# myChip register map
Vendor: ARM Ltd.; Series: ARMCM3; File version: 1.2
CPU: CM3 r2p1, little endian, no MPU, no FPU, 3 interrupt priority bits
Registers are 32-bit, read-write, reset 0x0 unless marked. A register's access mark holds for its fields unless they carry their own. Offsets are from the block's base; [hi:lo] are bit positions; {n}, {i} and the like mark numbered series.

## HRPWM_COM
Base 0x4003BF00
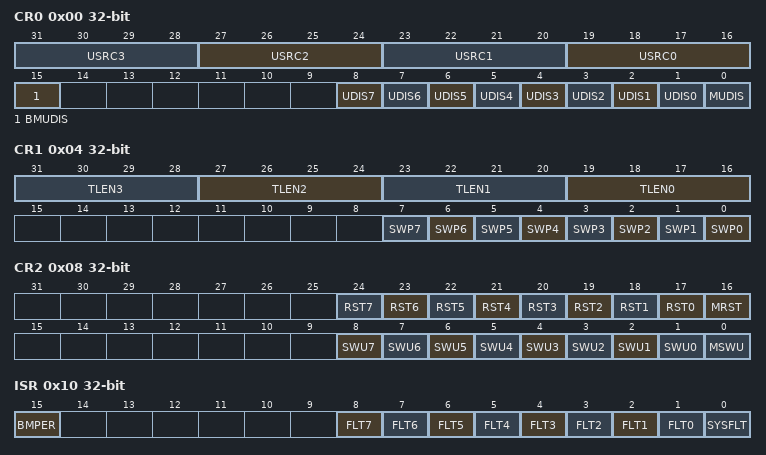
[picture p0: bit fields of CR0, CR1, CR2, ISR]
0x00 CR0 — HRPWM Control Register0
  [4n+19:4n+16] USRC{n} (n=0..3) — Adc Trigger {n} 更新来源
  [15] BMUDIS — Burst Mode 更新禁止
  [n+1] UDIS{n} (n=0..7) — PWM{n} 更新禁止
  [0] MUDIS — Master PWM 更新禁止
0x04 CR1 — HRPWM Control Register1
  [4n+19:4n+16] TLEN{n} (n=0..3) — Adc Trigger {n} 事件长度
  [n] SWP{n} (n=0..7) — PWM{n} 输出交换
0x08 CR2 — HRPWM Control Register2
  [n+17] RST{n} (n=0..7) — PWM{n} 软件复位
  [16] MRST — Master PWM 软件复位
  [n+1] SWU{n} (n=0..7) — PWM{n} 软件更新
  [0] MSWU — Master PWM 软件更新
0x10 ISR — HRPWM Interrupt Status Register
  [15] BMPER — Burst Mode Period 中断标志
  [n+1] FLT{n} (n=0..7) — Fault {n} 中断标志
  [0] SYSFLT — System Fault 中断标志
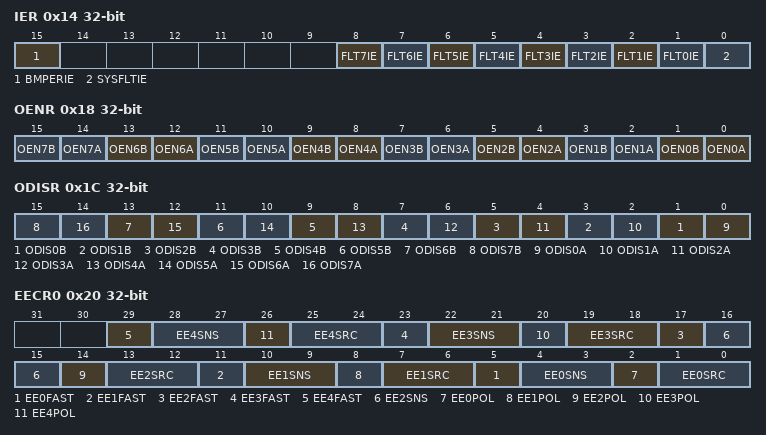
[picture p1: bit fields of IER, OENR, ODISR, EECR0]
0x14 IER — HRPWM Interrupt Enable Register
  [15] BMPERIE — Burst Mode Period 中断使能
  [n+1] FLT{n}IE (n=0..7) — Fault {n} 中断使能
  [0] SYSFLTIE — System Fault 中断使能
0x18 OENR — HRPWM Output Enable Register
  [2n+1] OEN{n}B (n=0..7) — PWM{n} Out B启动
  [2n] OEN{n}A (n=0..7) — PWM{n} Out A启动
0x1C ODISR — HRPWM Output Disable Register
  [2n+1] ODIS{n}B (n=0..7) — PWM{n} Out B停止
  [2n] ODIS{n}A (n=0..7) — PWM{n} Out A停止
0x20 EECR0 — HRPWM External Event Control Register0
  [6n+5] EE{n}FAST (n=0..4) — Event {n} 快速模式
  [6n+4:6n+3] EE{n}SNS (n=0..4) — Event {n} 输入有效沿
  [6n+2] EE{n}POL (n=0..4) — Event {n} 输入极性
  [6n+1:6n] EE{n}SRC (n=0..4) — Event {n} 输入来源
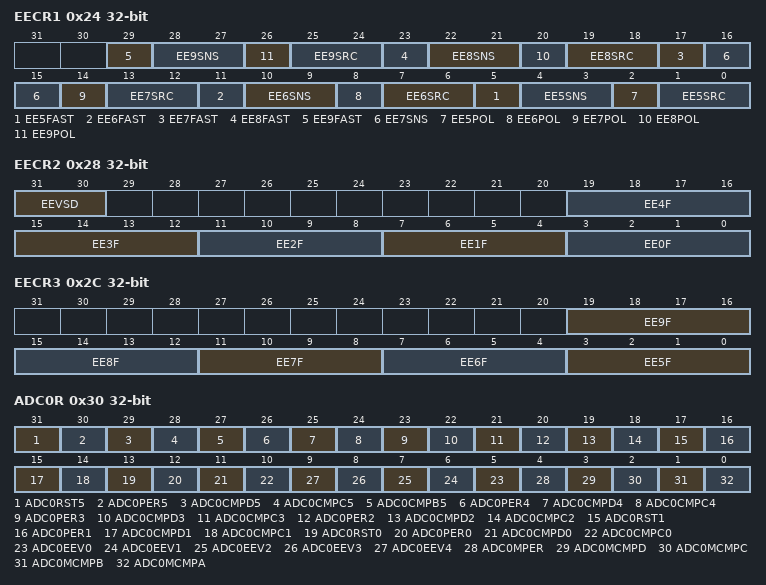
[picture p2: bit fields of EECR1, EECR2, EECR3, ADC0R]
0x24 EECR1 — HRPWM External Event Control Register1
  [6n-25] EE{n}FAST (n=5..9) — Event {n} 快速模式
  [6n-26:6n-27] EE{n}SNS (n=5..9) — Event {n} 输入有效沿
  [6n-28] EE{n}POL (n=5..9) — Event {n} 输入极性
  [6n-29:6n-30] EE{n}SRC (n=5..9) — Event {n} 输入来源
0x28 EECR2 — HRPWM External Event Control Register2
  [31:30] EEVSD — Event 采样时钟分频比例
  [4n+3:4n] EE{n}F (n=0..4) — Event {n} 滤波长度
0x2C EECR3 — HRPWM External Event Control Register3
  [4n-17:4n-20] EE{n}F (n=5..9) — Event {n} 滤波长度
0x30 ADC0R — HRPWM ADC Trigger Register 0
  [31] ADC0RST5 — PWM5 Reset/RollOver事件会产生Adc Trigger 0
  [30] ADC0PER5 — PWM5 Period事件会产生Adc Trigger 0
  [29] ADC0CMPD5 — PWM5 Compare D事件会产生Adc Trigger 0
  [28] ADC0CMPC5 — PWM5 Compare C事件会产生Adc Trigger 0
  [27] ADC0CMPB5 — PWM5 Compare B事件会产生Adc Trigger 0
  [26] ADC0PER4 — PWM4 Period事件会产生Adc Trigger 0
  [25] ADC0CMPD4 — PWM4 Compare D事件会产生Adc Trigger 0
  [24] ADC0CMPC4 — PWM4 Compare C事件会产生Adc Trigger 0
  [23] ADC0PER3 — PWM3 Period事件会产生Adc Trigger 0
  [22] ADC0CMPD3 — PWM3 Compare D事件会产生Adc Trigger 0
  [21] ADC0CMPC3 — PWM3 Compare C事件会产生Adc Trigger 0
  [20] ADC0PER2 — PWM2 Period事件会产生Adc Trigger 0
  [19] ADC0CMPD2 — PWM2 Compare D事件会产生Adc Trigger 0
  [18] ADC0CMPC2 — PWM2 Compare C事件会产生Adc Trigger 0
  [17] ADC0RST1 — PWM1 Reset/RollOver事件会产生Adc Trigger 0
  [16] ADC0PER1 — PWM1 Period事件会产生Adc Trigger 0
  [15] ADC0CMPD1 — PWM1 Compare D事件会产生Adc Trigger 0
  [14] ADC0CMPC1 — PWM1 Compare C事件会产生Adc Trigger 0
  [13] ADC0RST0 — PWM0 Reset/RollOver事件会产生Adc Trigger 0
  [12] ADC0PER0 — PWM0 Period事件会产生Adc Trigger 0
  [11] ADC0CMPD0 — PWM0 Compare D事件会产生Adc Trigger 0
  [10] ADC0CMPC0 — PWM0 Compare C事件会产生Adc Trigger 0
  [n+5] ADC0EEV{n} (n=0..4) — External Event {n}事件会产生Adc Trigger 0
  [4] ADC0MPER — Master PWM Period事件会产生Adc Trigger 0
  [3] ADC0MCMPD — Master PWM Compare D事件会产生Adc Trigger 0
  [2] ADC0MCMPC — Master PWM Compare C事件会产生Adc Trigger 0
  [1] ADC0MCMPB — Master PWM Compare B事件会产生Adc Trigger 0
  [0] ADC0MCMPA — Master PWM Compare A事件会产生Adc Trigger 0
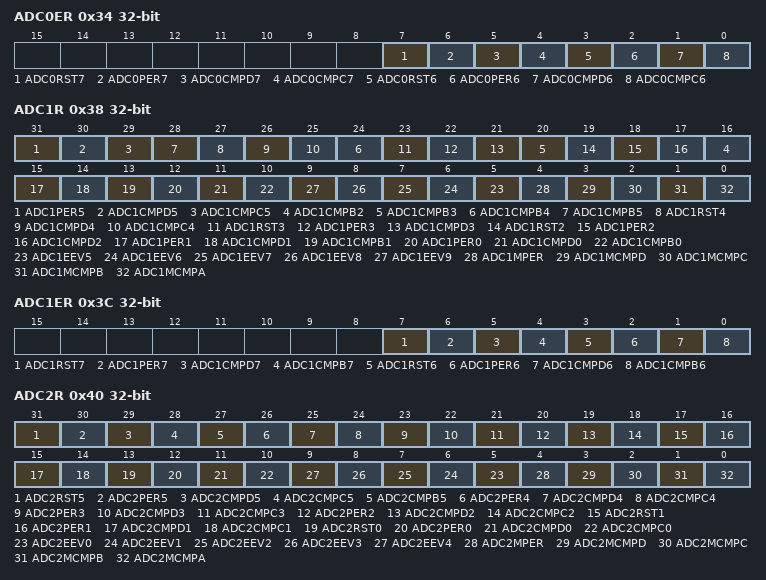
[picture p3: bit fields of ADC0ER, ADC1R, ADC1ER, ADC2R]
0x34 ADC0ER — HRPWM ADC Trigger Extended Register 0
  [7] ADC0RST7 — PWM7 Reset/RollOver事件会产生Adc Trigger 0
  [6] ADC0PER7 — PWM7 Period事件会产生Adc Trigger 0
  [5] ADC0CMPD7 — PWM7 Compare D事件会产生Adc Trigger 0
  [4] ADC0CMPC7 — PWM7 Compare C事件会产生Adc Trigger 0
  [3] ADC0RST6 — PWM6 Reset/RollOver事件会产生Adc Trigger 0
  [2] ADC0PER6 — PWM6 Period事件会产生Adc Trigger 0
  [1] ADC0CMPD6 — PWM6 Compare D事件会产生Adc Trigger 0
  [0] ADC0CMPC6 — PWM6 Compare C事件会产生Adc Trigger 0
0x38 ADC1R — HRPWM ADC Trigger Register 1
  [31] ADC1PER5 — PWM5 Period事件会产生Adc Trigger 1
  [30] ADC1CMPD5 — PWM5 Compare D事件会产生Adc Trigger 1
  [29] ADC1CMPC5 — PWM5 Compare C事件会产生Adc Trigger 1
  [4n+8] ADC1CMPB{n} (n=2..5) — PWM{n} Compare B事件会产生Adc Trigger 1
  [27] ADC1RST4 — PWM4 Reset/RollOver事件会产生Adc Trigger 1
  [26] ADC1CMPD4 — PWM4 Compare D事件会产生Adc Trigger 1
  [25] ADC1CMPC4 — PWM4 Compare C事件会产生Adc Trigger 1
  [23] ADC1RST3 — PWM3 Reset/RollOver事件会产生Adc Trigger 1
  [22] ADC1PER3 — PWM3 Period事件会产生Adc Trigger 1
  [21] ADC1CMPD3 — PWM3 Compare D事件会产生Adc Trigger 1
  [19] ADC1RST2 — PWM2 Reset/RollOver事件会产生Adc Trigger 1
  [18] ADC1PER2 — PWM2 Period事件会产生Adc Trigger 1
  [17] ADC1CMPD2 — PWM2 Compare D事件会产生Adc Trigger 1
  [15] ADC1PER1 — PWM1 Period事件会产生Adc Trigger 1
  [14] ADC1CMPD1 — PWM1 Compare D事件会产生Adc Trigger 1
  [13] ADC1CMPB1 — PWM1 Compare B事件会产生Adc Trigger 1
  [12] ADC1PER0 — PWM0 Period事件会产生Adc Trigger 1
  [11] ADC1CMPD0 — PWM0 Compare D事件会产生Adc Trigger 1
  [10] ADC1CMPB0 — PWM0 Compare B事件会产生Adc Trigger 1
  [n] ADC1EEV{n} (n=5..9) — External Event {n}事件会产生Adc Trigger 1
  [4] ADC1MPER — Master PWM Period事件会产生Adc Trigger 1
  [3] ADC1MCMPD — Master PWM Compare D事件会产生Adc Trigger 1
  [2] ADC1MCMPC — Master PWM Compare C事件会产生Adc Trigger 1
  [1] ADC1MCMPB — Master PWM Compare B事件会产生Adc Trigger 1
  [0] ADC1MCMPA — Master PWM Compare A事件会产生Adc Trigger 1
0x3C ADC1ER — HRPWM ADC Trigger Extended Register 1
  [7] ADC1RST7 — PWM7 Reset/RollOver事件会产生Adc Trigger 1
  [6] ADC1PER7 — PWM7 Period事件会产生Adc Trigger 1
  [5] ADC1CMPD7 — PWM7 Compare D事件会产生Adc Trigger 1
  [4] ADC1CMPB7 — PWM7 Compare B事件会产生Adc Trigger 1
  [3] ADC1RST6 — PWM6 Reset/RollOver事件会产生Adc Trigger 1
  [2] ADC1PER6 — PWM6 Period事件会产生Adc Trigger 1
  [1] ADC1CMPD6 — PWM6 Compare D事件会产生Adc Trigger 1
  [0] ADC1CMPB6 — PWM6 Compare B事件会产生Adc Trigger 1
0x40 ADC2R — HRPWM ADC Trigger Register 2
  [31] ADC2RST5 — PWM5 Reset/RollOver事件会产生Adc Trigger 2
  [30] ADC2PER5 — PWM5 Period事件会产生Adc Trigger 2
  [29] ADC2CMPD5 — PWM5 Compare D事件会产生Adc Trigger 2
  [28] ADC2CMPC5 — PWM5 Compare C事件会产生Adc Trigger 2
  [27] ADC2CMPB5 — PWM5 Compare B事件会产生Adc Trigger 2
  [26] ADC2PER4 — PWM4 Period事件会产生Adc Trigger 2
  [25] ADC2CMPD4 — PWM4 Compare D事件会产生Adc Trigger 2
  [24] ADC2CMPC4 — PWM4 Compare C事件会产生Adc Trigger 2
  [23] ADC2PER3 — PWM3 Period事件会产生Adc Trigger 2
  [22] ADC2CMPD3 — PWM3 Compare D事件会产生Adc Trigger 2
  [21] ADC2CMPC3 — PWM3 Compare C事件会产生Adc Trigger 2
  [20] ADC2PER2 — PWM2 Period事件会产生Adc Trigger 2
  [19] ADC2CMPD2 — PWM2 Compare D事件会产生Adc Trigger 2
  [18] ADC2CMPC2 — PWM2 Compare C事件会产生Adc Trigger 2
  [17] ADC2RST1 — PWM1 Reset/RollOver事件会产生Adc Trigger 2
  [16] ADC2PER1 — PWM1 Period事件会产生Adc Trigger 2
  [15] ADC2CMPD1 — PWM1 Compare D事件会产生Adc Trigger 2
  [14] ADC2CMPC1 — PWM1 Compare C事件会产生Adc Trigger 2
  [13] ADC2RST0 — PWM0 Reset/RollOver事件会产生Adc Trigger 2
  [12] ADC2PER0 — PWM0 Period事件会产生Adc Trigger 2
  [11] ADC2CMPD0 — PWM0 Compare D事件会产生Adc Trigger 2
  [10] ADC2CMPC0 — PWM0 Compare C事件会产生Adc Trigger 2
  [n+5] ADC2EEV{n} (n=0..4) — External Event {n}事件会产生Adc Trigger 2
  [4] ADC2MPER — Master PWM Period事件会产生Adc Trigger 2
  [3] ADC2MCMPD — Master PWM Compare D事件会产生Adc Trigger 2
  [2] ADC2MCMPC — Master PWM Compare C事件会产生Adc Trigger 2
  [1] ADC2MCMPB — Master PWM Compare B事件会产生Adc Trigger 2
  [0] ADC2MCMPA — Master PWM Compare A事件会产生Adc Trigger 2
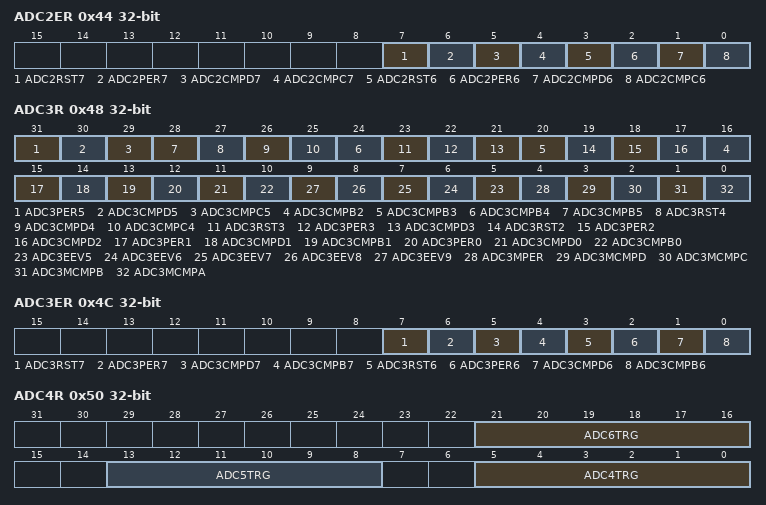
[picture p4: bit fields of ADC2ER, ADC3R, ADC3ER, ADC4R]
0x44 ADC2ER — HRPWM ADC Trigger Extended Register 2
  [7] ADC2RST7 — PWM7 Reset/RollOver事件会产生Adc Trigger 2
  [6] ADC2PER7 — PWM7 Period事件会产生Adc Trigger 2
  [5] ADC2CMPD7 — PWM7 Compare D事件会产生Adc Trigger 2
  [4] ADC2CMPC7 — PWM7 Compare C事件会产生Adc Trigger 2
  [3] ADC2RST6 — PWM6 Reset/RollOver事件会产生Adc Trigger 2
  [2] ADC2PER6 — PWM6 Period事件会产生Adc Trigger 2
  [1] ADC2CMPD6 — PWM6 Compare D事件会产生Adc Trigger 2
  [0] ADC2CMPC6 — PWM6 Compare C事件会产生Adc Trigger 2
0x48 ADC3R — HRPWM ADC Trigger Register 3
  [31] ADC3PER5 — PWM5 Period事件会产生Adc Trigger 3
  [30] ADC3CMPD5 — PWM5 Compare D事件会产生Adc Trigger 3
  [29] ADC3CMPC5 — PWM5 Compare C事件会产生Adc Trigger 3
  [4n+8] ADC3CMPB{n} (n=2..5) — PWM{n} Compare B事件会产生Adc Trigger 3
  [27] ADC3RST4 — PWM4 Reset/RollOver事件会产生Adc Trigger 3
  [26] ADC3CMPD4 — PWM4 Compare D事件会产生Adc Trigger 3
  [25] ADC3CMPC4 — PWM4 Compare C事件会产生Adc Trigger 3
  [23] ADC3RST3 — PWM3 Reset/RollOver事件会产生Adc Trigger 3
  [22] ADC3PER3 — PWM3 Period事件会产生Adc Trigger 3
  [21] ADC3CMPD3 — PWM3 Compare D事件会产生Adc Trigger 3
  [19] ADC3RST2 — PWM2 Reset/RollOver事件会产生Adc Trigger 3
  [18] ADC3PER2 — PWM2 Period事件会产生Adc Trigger 3
  [17] ADC3CMPD2 — PWM2 Compare D事件会产生Adc Trigger 3
  [15] ADC3PER1 — PWM1 Period事件会产生Adc Trigger 3
  [14] ADC3CMPD1 — PWM1 Compare D事件会产生Adc Trigger 3
  [13] ADC3CMPB1 — PWM1 Compare B事件会产生Adc Trigger 3
  [12] ADC3PER0 — PWM0 Period事件会产生Adc Trigger 3
  [11] ADC3CMPD0 — PWM0 Compare D事件会产生Adc Trigger 3
  [10] ADC3CMPB0 — PWM0 Compare B事件会产生Adc Trigger 3
  [n] ADC3EEV{n} (n=5..9) — External Event {n}事件会产生Adc Trigger 3
  [4] ADC3MPER — Master PWM Period事件会产生Adc Trigger 3
  [3] ADC3MCMPD — Master PWM Compare D事件会产生Adc Trigger 3
  [2] ADC3MCMPC — Master PWM Compare C事件会产生Adc Trigger 3
  [1] ADC3MCMPB — Master PWM Compare B事件会产生Adc Trigger 3
  [0] ADC3MCMPA — Master PWM Compare A事件会产生Adc Trigger 3
0x4C ADC3ER — HRPWM ADC Trigger Extended Register 3
  [7] ADC3RST7 — PWM7 Reset/RollOver事件会产生Adc Trigger 3
  [6] ADC3PER7 — PWM7 Period事件会产生Adc Trigger 3
  [5] ADC3CMPD7 — PWM7 Compare D事件会产生Adc Trigger 3
  [4] ADC3CMPB7 — PWM7 Compare B事件会产生Adc Trigger 3
  [3] ADC3RST6 — PWM6 Reset/RollOver事件会产生Adc Trigger 3
  [2] ADC3PER6 — PWM6 Period事件会产生Adc Trigger 3
  [1] ADC3CMPD6 — PWM6 Compare D事件会产生Adc Trigger 3
  [0] ADC3CMPB6 — PWM6 Compare B事件会产生Adc Trigger 3
0x50 ADC4R — HRPWM ADC Trigger Register 4
  [21:16] ADC6TRG — Adc Trigger 6 来源
  [13:8] ADC5TRG — Adc Trigger 5 来源
  [5:0] ADC4TRG — Adc Trigger 4 来源
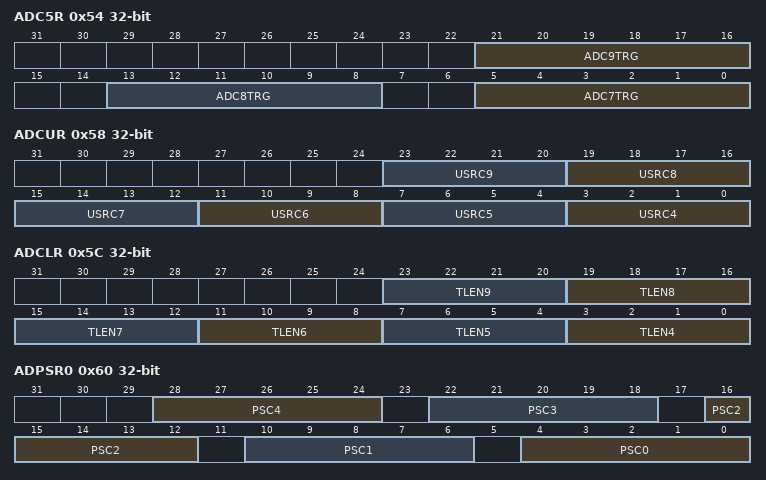
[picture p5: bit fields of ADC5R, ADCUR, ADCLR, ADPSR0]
0x54 ADC5R — HRPWM ADC Trigger Register 5
  [21:16] ADC9TRG — Adc Trigger 9 来源
  [13:8] ADC8TRG — Adc Trigger 8 来源
  [5:0] ADC7TRG — Adc Trigger 7 来源
0x58 ADCUR — HRPWM ADC Update Register
  [4n-13:4n-16] USRC{n} (n=4..9) — Adc Trigger {n} 更新来源
0x5C ADCLR — HRPWM ADC Length Register
  [4n-13:4n-16] TLEN{n} (n=4..9) — Adc Trigger {n} 事件长度
0x60 ADPSR0 — HRPWM ADC Trigger Post Scaler Register0
  [6n+4:6n] PSC{n} (n=0..4) — Adc Trigger {n} 降采样比例
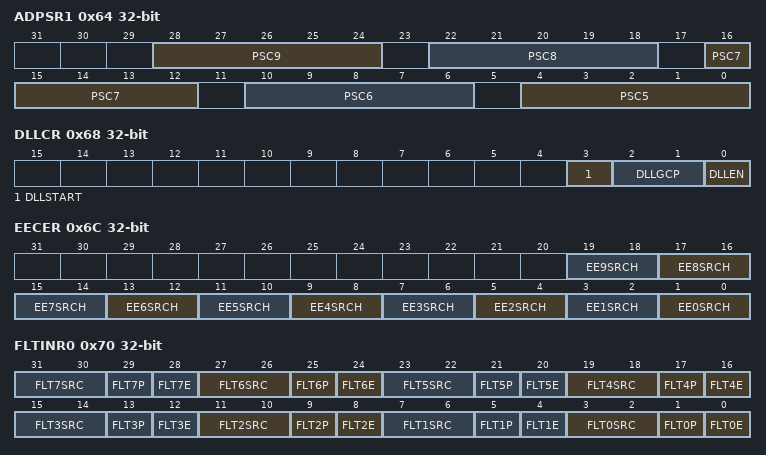
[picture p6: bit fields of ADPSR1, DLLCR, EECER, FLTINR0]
0x64 ADPSR1 — HRPWM ADC Trigger Post Scaler Register1
  [6n-26:6n-30] PSC{n} (n=5..9) — Adc Trigger {n} 降采样比例
0x68 DLLCR — HRPWM DLL Control Register
  [3] DLLSTART — DLL 启动位
  [2:1] DLLGCP — DLL 电流选择位
  [0] DLLEN — DLL 使能位
0x6C EECER — HRPWM External Event Control Extended Register
  [2n+1:2n] EE{n}SRCH (n=0..9) — Event {n} 输入来源高位
0x70 FLTINR0 — HRPWM Fault Input Register0
  [4n+3:4n+2] FLT{n}SRC (n=0..7) — Fault {n} 输入来源
  [4n+1] FLT{n}P (n=0..7) — Fault {n} 输入极性
  [4n] FLT{n}E (n=0..7) — Fault {n} 输入使能
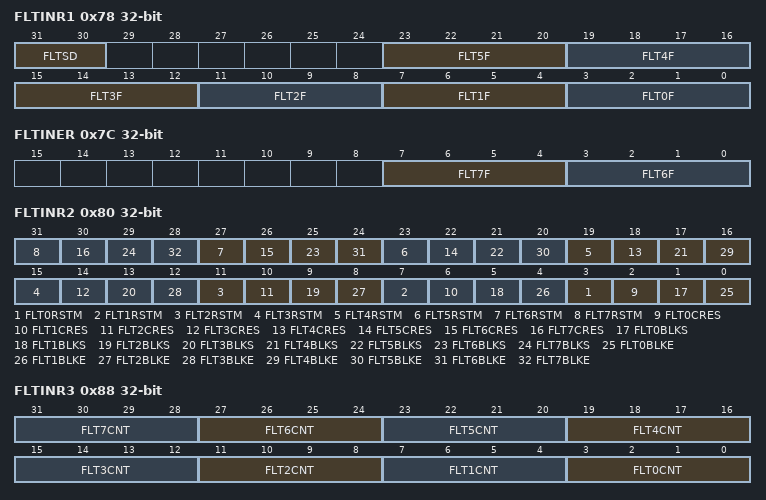
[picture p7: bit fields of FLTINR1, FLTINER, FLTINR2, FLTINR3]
0x78 FLTINR1 — HRPWM Fault Input Register1
  [31:30] FLTSD — Fault 采样时钟分频比例
  [4n+3:4n] FLT{n}F (n=0..5) — Fault {n} 滤波长度
0x7C FLTINER — HRPWM Fault Input Extend Register
  [7:4] FLT7F — Fault 7 滤波长度
  [3:0] FLT6F — Fault 6 滤波长度
0x80 FLTINR2 — HRPWM Fault Input Register2
  [4n+3] FLT{n}RSTM (n=0..7) — Fault {n} 复位模式
  [4n+2] FLT{n}CRES (n=0..7) — Fault {n} 计数复位
  [4n+1] FLT{n}BLKS (n=0..7) — Fault {n} 消隐源（窗口大小由PWM{n}决定）
  [4n] FLT{n}BLKE (n=0..7) — Fault {n} 消隐使能
0x88 FLTINR3 — HRPWM Fault Input Register3
  [4n+3:4n] FLT{n}CNT (n=0..7) — Fault {n} 计数阈值
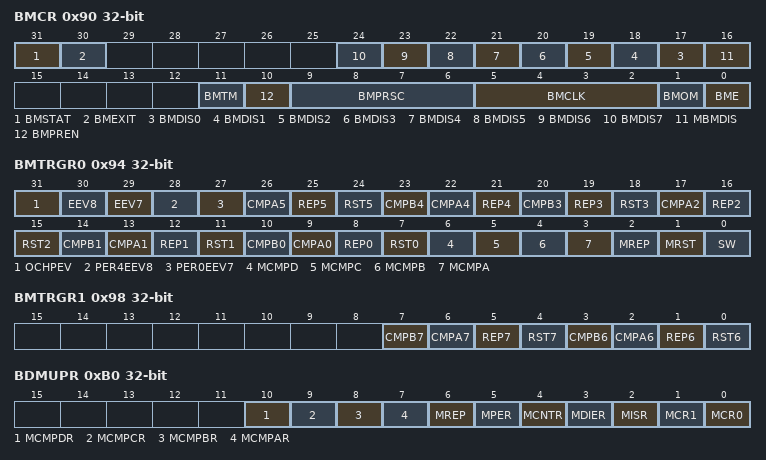
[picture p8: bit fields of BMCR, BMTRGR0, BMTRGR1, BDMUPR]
0x90 BMCR — HRPWM Burst Mode Control Register
  [31] BMSTAT ro — Burst Mode状态
  [30] BMEXIT — Burst Mode 强制退出
  [n+17] BMDIS{n} (n=0..7) — Burst Mode下PWM{n} 计数停止
  [16] MBMDIS — Burst Mode下Master PWM 计数停止
  [11] BMTM — Burst Mode 触发模式
  [10] BMPREN — Burst Mode 预加载使能
  [9:6] BMPRSC — Burst Mode 预分频
  [5:2] BMCLK — Burst Mode 时钟来源
  [1] BMOM — Burst Mode 工作模式
  [0] BME — Burst Mode 使能
0x94 BMTRGR0 — HRPWM Burst Mode Trigger Register 0
  [31] OCHPEV — TMR8_TRGO 事件会启动 Burst Mode
  [30] EEV8 — PWM4 Event 8 事件会启动 Burst Mode
  [29] EEV7 — PWM0 Event 7 事件会启动 Burst Mode
  [28] PER4EEV8 — PWM4 Event 8 事件后的 Period 事件会启动 Burst Mode
  [27] PER0EEV7 — PWM0 Event 7 事件后的 Period 事件会启动 Burst Mode
  [26] CMPA5 — PWM5 Compare A 事件会启动 Burst Mode
  [25] REP5 — PWM5 Repet 事件会启动 Burst Mode
  [24] RST5 — PWM5 Reset/RollOver 事件会启动 Burst Mode
  [23] CMPB4 — PWM4 Compare B 事件会启动 Burst Mode
  [22] CMPA4 — PWM4 Compare A 事件会启动 Burst Mode
  [21] REP4 — PWM4 Repet 事件会启动 Burst Mode
  [20] CMPB3 — PWM3 Compare A 事件会启动 Burst Mode
  [19] REP3 — PWM3 Repet 事件会启动 Burst Mode
  [18] RST3 — PWM3 Reset/RollOver 事件会启动 Burst Mode
  [17] CMPA2 — PWM2 Compare A 事件会启动 Burst Mode
  [16] REP2 — PWM2 Repet 事件会启动 Burst Mode
  [15] RST2 — PWM2 Reset/RollOver 事件会启动 Burst Mode
  [14] CMPB1 — PWM1 Compare B 事件会启动 Burst Mode
  [13] CMPA1 — PWM1 Compare A 事件会启动 Burst Mode
  [12] REP1 — PWM1 Repet 事件会启动 Burst Mode
  [11] RST1 — PWM1 Reset/RollOver 事件会启动 Burst Mode
  [10] CMPB0 — PWM0 Compare B 事件会启动 Burst Mode
  [9] CMPA0 — PWM0 Compare A 事件会启动 Burst Mode
  [8] REP0 — PWM0 Repet 事件会启动 Burst Mode
  [7] RST0 — PWM0 Reset/RollOver 事件会启动 Burst Mode
  [6] MCMPD — Master PWM Compare D事件会启动 Burst Mode
  [5] MCMPC — Master PWM Compare C事件会启动 Burst Mode
  [4] MCMPB — Master PWM Compare B事件会启动 Burst Mode
  [3] MCMPA — Master PWM Compare A事件会启动 Burst Mode
  [2] MREP — Master PWM Repet事件会启动 Burst Mode
  [1] MRST — Master PWM Reset/Rollover事件会启动 Burst Mode
  [0] SW — Software 事件启动 Burst Mode
0x98 BMTRGR1 — HRPWM Burst Mode Trigger Register 1
  [7] CMPB7 — PWM7 Compare B 事件会启动 Burst Mode
  [6] CMPA7 — PWM7 Compare A 事件会启动 Burst Mode
  [5] REP7 — PWM7 Repet 事件会启动 Burst Mode
  [4] RST7 — PWM7 Reset/RollOver 事件会启动 Burst Mode
  [3] CMPB6 — PWM6 Compare B 事件会启动 Burst Mode
  [2] CMPA6 — PWM6 Compare A 事件会启动 Burst Mode
  [1] REP6 — PWM6 Repet 事件会启动 Burst Mode
  [0] RST6 — PWM6 Reset/RollOver 事件会启动 Burst Mode
0xA0 BMPER — HRPWM Burst Mode Period Register
  [15:0] BMPER — Burst Mode Period 数值
0xA4 BMCMPR — HRPWM Burst Mode Compare Register
  [15:0] BMCMP — Burst Mode Compare 数值
0xB0 BDMUPR — HRPWM Burst DMA Master Update Register
  [10] MCMPDR — MCMPDR 寄存器支持 Burst DMA 读取缓存数据并更新
  [9] MCMPCR — MCMPCR 寄存器支持 Burst DMA 读取缓存数据并更新
  [8] MCMPBR — MCMPBR 寄存器支持 Burst DMA 读取缓存数据并更新
  [7] MCMPAR — MCMPAR 寄存器支持 Burst DMA 读取缓存数据并更新
  [6] MREP — MREP 寄存器支持 Burst DMA 读取缓存数据并更新
  [5] MPER — MPER 寄存器支持 Burst DMA 读取缓存数据并更新
  [4] MCNTR — MCNTR 寄存器支持 Burst DMA 读取缓存数据并更新
  [3] MDIER — MDIER 寄存器支持 Burst DMA 读取缓存数据并更新
  [2] MISR — MISR 寄存器支持 Burst DMA 读取缓存数据并更新
  [1] MCR1 — MCR1 寄存器支持 Burst DMA 读取缓存数据并更新
  [0] MCR0 — MCR0 寄存器支持 Burst DMA 读取缓存数据并更新
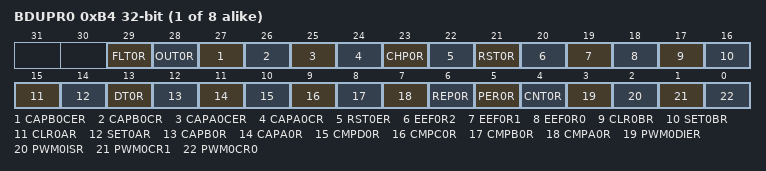
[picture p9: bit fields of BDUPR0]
{0xB4+4i} BDUPR{i} (i=0..7) — HRPWM Burst DMA Update Register {i}
  [29] FLT{i}R — FLT{i}R 寄存器支持 Burst DMA 读取缓存数据并更新
  [28] OUT{i}R — OUT{i}R 寄存器支持 Burst DMA 读取缓存数据并更新
  [27] CAPB{i}CER — CAPB{i}CER 寄存器支持 Burst DMA 读取缓存数据并更新
  [26] CAPB{i}CR — CAPB{i}CR 寄存器支持 Burst DMA 读取缓存数据并更新
  [25] CAPA{i}CER — CAPA{i}CER 寄存器支持 Burst DMA 读取缓存数据并更新
  [24] CAPA{i}CR — CAPA{i}CR 寄存器支持 Burst DMA 读取缓存数据并更新
  [23] CHP{i}R — CHP{i}R 寄存器支持 Burst DMA 读取缓存数据并更新
  [22] RST{i}ER — RST{i}ER 寄存器支持 Burst DMA 读取缓存数据并更新
  [21] RST{i}R — RST{i}R 寄存器支持 Burst DMA 读取缓存数据并更新
  [20] EEF{i}R2 — EEF{i}R2 寄存器支持 Burst DMA 读取缓存数据并更新
  [19] EEF{i}R1 — EEF{i}R1 寄存器支持 Burst DMA 读取缓存数据并更新
  [18] EEF{i}R0 — EEF{i}R0 寄存器支持 Burst DMA 读取缓存数据并更新
  [17] CLR{i}BR — CLR{i}BR 寄存器支持 Burst DMA 读取缓存数据并更新
  [16] SET{i}BR — SET{i}BR 寄存器支持 Burst DMA 读取缓存数据并更新
  [15] CLR{i}AR — CLR{i}AR 寄存器支持 Burst DMA 读取缓存数据并更新
  [14] SET{i}AR — SET{i}AR 寄存器支持 Burst DMA 读取缓存数据并更新
  [13] DT{i}R — DT{i}R 寄存器支持 Burst DMA 读取缓存数据并更新
  [12] CAPB{i}R — CAPB{i}R 寄存器支持 Burst DMA 将寄存器值写入缓存
  [11] CAPA{i}R — CAPA{i}R 寄存器支持 Burst DMA 将寄存器值写入缓存
  [10] CMPD{i}R — CMPD{i}R 寄存器支持 Burst DMA 读取缓存数据并更新
  [9] CMPC{i}R — CMPC{i}R 寄存器支持 Burst DMA 读取缓存数据并更新
  [8] CMPB{i}R — CMPB{i}R 寄存器支持 Burst DMA 读取缓存数据并更新
  [7] CMPA{i}R — CMPA{i}R 寄存器支持 Burst DMA 读取缓存数据并更新
  [6] REP{i}R — REP{i}R 寄存器支持 Burst DMA 读取缓存数据并更新
  [5] PER{i}R — PER{i}R 寄存器支持 Burst DMA 读取缓存数据并更新
  [4] CNT{i}R — CNT{i}R 寄存器支持 Burst DMA 读取缓存数据并更新
  [3] PWM{i}DIER — PWM{i}DIER 寄存器支持 Burst DMA 读取缓存数据并更新
  [2] PWM{i}ISR — PWM{i}ISR 寄存器支持 Burst DMA 读取缓存数据并更新
  [1] PWM{i}CR1 — PWM{i}CR1 寄存器支持 Burst DMA 读取缓存数据并更新
  [0] PWM{i}CR0 — PWM{i}CR0 寄存器支持 Burst DMA 读取缓存数据并更新
0xE0 BDMWADR — HRPWM Burst DMA Write Address Register
  [31:0] BDMADR — Burst DMA 写起始地址
0xF0 BDMADR — HRPWM Burst DMA Read Address Register
  [31:0] BDMADR — Burst DMA 读起始地址
